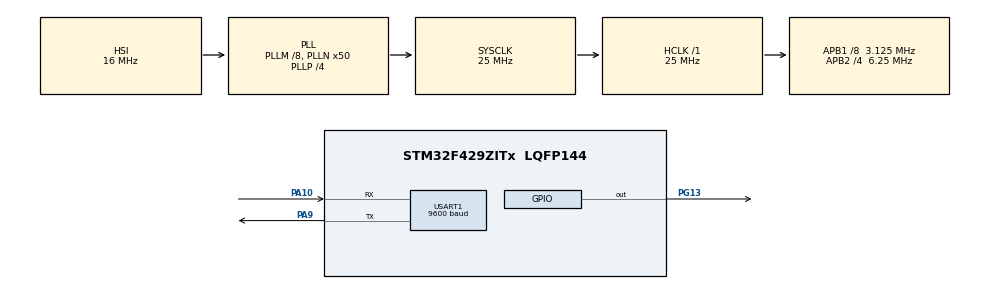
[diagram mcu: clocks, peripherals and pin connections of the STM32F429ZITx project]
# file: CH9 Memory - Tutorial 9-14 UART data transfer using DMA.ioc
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Dma.Request0=USART1_TX
Dma.USART1_TX.0.Direction=DMA_MEMORY_TO_PERIPH
Dma.USART1_TX.0.FIFOMode=DMA_FIFOMODE_DISABLE
Dma.USART1_TX.0.Instance=DMA2_Stream7
Dma.USART1_TX.0.MemDataAlignment=DMA_MDATAALIGN_BYTE
Dma.USART1_TX.0.MemInc=DMA_MINC_ENABLE
Dma.USART1_TX.0.Mode=DMA_NORMAL
Dma.USART1_TX.0.PeriphDataAlignment=DMA_PDATAALIGN_BYTE
Dma.USART1_TX.0.PeriphInc=DMA_PINC_DISABLE
Dma.USART1_TX.0.Priority=DMA_PRIORITY_LOW
Mcu.Family=STM32F4
Mcu.Name=STM32F429ZITx
Mcu.Package=LQFP144
NVIC.DMA2_Stream7_IRQn=true\:0\:0\:false\:false\:true\:false\:true\:true
NVIC.PriorityGroup=NVIC_PRIORITYGROUP_1
NVIC.TIM1_UP_TIM10_IRQn=true\:1\:0\:true\:false\:true\:true\:true\:true
NVIC.USART1_IRQn=true\:1\:0\:true\:false\:true\:true\:true\:true
PA10.Mode=Asynchronous
PA10.Signal=USART1_RX
PA9.Mode=Asynchronous
PA9.Signal=USART1_TX
PG13.Signal=GPIO_Output
ProjectManager.HeapSize=0x200
ProjectManager.StackSize=0x400
ProjectManager.TargetToolchain=STM32CubeIDE
RCC.48MHZClocksFreq_Value=14285714.285714285
RCC.AHBFreq_Value=25000000
RCC.APB1CLKDivider=RCC_HCLK_DIV8
RCC.APB1Freq_Value=3125000
RCC.APB1TimFreq_Value=6250000
RCC.APB2CLKDivider=RCC_HCLK_DIV4
RCC.APB2Freq_Value=6250000
RCC.APB2TimFreq_Value=12500000
RCC.CortexFreq_Value=25000000
RCC.HCLKFreq_Value=25000000
RCC.HSE_VALUE=8000000
RCC.HSI_VALUE=16000000
RCC.LSE_VALUE=32768
RCC.PLLM=8
RCC.PLLN=50
RCC.PLLP=RCC_PLLP_DIV4
RCC.PLLQ=7
RCC.SYSCLKFreq_VALUE=25000000
RCC.SYSCLKSource=RCC_SYSCLKSOURCE_PLLCLK
RCC.VCOOutputFreq_Value=100000000
TIM1.Period=1000-1
TIM1.Prescaler=12500-1
USART1.BaudRate=9600
USART1.VirtualMode=VM_ASYNC
VP_TIM1_VS_ClockSourceINT.Mode=Internal
board=STM32F429I-DISC1

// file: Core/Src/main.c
/* USER CODE BEGIN Header */
/**
  ******************************************************************************
  * @file           : main.c
  * @brief          : Main program body
  ******************************************************************************
  * @attention
  *
  * Copyright (c) 2024 STMicroelectronics.
  * All rights reserved.
  *
  * This software is licensed under terms that can be found in the LICENSE file
  * in the root directory of this software component.
  * If no LICENSE file comes with this software, it is provided AS-IS.
  *
  ******************************************************************************
  */

	/***************************** Tutorial Tags ******************************
	 Data communication UART Tx, and DMA
	 Timer interrupts
	 GPIO digital output
	 **************************************************************************/

	/* 9.4.5 DMA Usage in C Language: ******************************************
	* Tutorial 9-14: UART data transfer using the DMA module
	*

    In this tutorial on memory to peripheral unit transfer using UART module
    form a project with the following specificvation:

    Every second, Long string will be transmitted to PC via UART using DMA. The
    green LED, connected to pin PG13 of the STM32F4 board, will be toggled every time
    to track data transfer. We will use interrupt of the Timer 1 module to obtain 1 s
    intervals.
	***************************************************************************/
/* USER CODE END Header */
#include "main.h"

/* USER CODE BEGIN Includes */
#include<string.h>
/* USER CODE END Includes */

TIM_HandleTypeDef htim1;

UART_HandleTypeDef huart1;
DMA_HandleTypeDef hdma_usart1_tx;

/* USER CODE BEGIN PV */
char * msg = {"Hello world****************************************************\
		******************************************************************** \
		******************************************************************** \
		*********************************************************************\
		********************************************************************* \
		********************************************************************** \
		*******************************************************Hello world end""\r\n"};
/* USER CODE END PV */

void SystemClock_Config(void);
static void MX_GPIO_Init(void);
static void MX_DMA_Init(void);
static void MX_USART1_UART_Init(void);
static void MX_TIM1_Init(void);

int main(void)
{

  /* MCU Configuration--------------------------------------------------------*/

  /* Reset of all peripherals, Initializes the Flash interface and the Systick. */
  HAL_Init();

  /* Configure the system clock */
  SystemClock_Config();

  /* Initialize all configured peripherals */
  MX_GPIO_Init();
  MX_DMA_Init();
  MX_USART1_UART_Init();
  MX_TIM1_Init();
  /* USER CODE BEGIN 2 */
  // Clear timer update flag in case it is set at start
  if (__HAL_TIM_GET_FLAG(&htim1 , TIM_FLAG_UPDATE) != RESET)
  __HAL_TIM_CLEAR_FLAG(&htim1 , TIM_FLAG_UPDATE);
  // Start timer in interrupt mode
  HAL_TIM_Base_Start_IT(&htim1);

  /* USER CODE END 2 */

  /* Infinite loop */
  while (1)
  {

  }
}

void SystemClock_Config(void)
{
  RCC_OscInitTypeDef RCC_OscInitStruct = {0};
  RCC_ClkInitTypeDef RCC_ClkInitStruct = {0};

  /** Configure the main internal regulator output voltage
  */
  __HAL_RCC_PWR_CLK_ENABLE();
  __HAL_PWR_VOLTAGESCALING_CONFIG(PWR_REGULATOR_VOLTAGE_SCALE3);

  /** Initializes the RCC Oscillators according to the specified parameters
  * in the RCC_OscInitTypeDef structure.
  */
  RCC_OscInitStruct.OscillatorType = RCC_OSCILLATORTYPE_HSI;
  RCC_OscInitStruct.HSIState = RCC_HSI_ON;
  RCC_OscInitStruct.HSICalibrationValue = RCC_HSICALIBRATION_DEFAULT;
  RCC_OscInitStruct.PLL.PLLState = RCC_PLL_ON;
  RCC_OscInitStruct.PLL.PLLSource = RCC_PLLSOURCE_HSI;
  RCC_OscInitStruct.PLL.PLLM = 8;
  RCC_OscInitStruct.PLL.PLLN = 50;
  RCC_OscInitStruct.PLL.PLLP = RCC_PLLP_DIV4;
  RCC_OscInitStruct.PLL.PLLQ = 7;
  if (HAL_RCC_OscConfig(&RCC_OscInitStruct) != HAL_OK)
  {
    Error_Handler();
  }

  /** Initializes the CPU, AHB and APB buses clocks
  */
  RCC_ClkInitStruct.ClockType = RCC_CLOCKTYPE_HCLK|RCC_CLOCKTYPE_SYSCLK
                              |RCC_CLOCKTYPE_PCLK1|RCC_CLOCKTYPE_PCLK2;
  RCC_ClkInitStruct.SYSCLKSource = RCC_SYSCLKSOURCE_PLLCLK;
  RCC_ClkInitStruct.AHBCLKDivider = RCC_SYSCLK_DIV1;
  RCC_ClkInitStruct.APB1CLKDivider = RCC_HCLK_DIV8;
  RCC_ClkInitStruct.APB2CLKDivider = RCC_HCLK_DIV4;

  if (HAL_RCC_ClockConfig(&RCC_ClkInitStruct, FLASH_LATENCY_0) != HAL_OK)
  {
    Error_Handler();
  }
}

static void MX_TIM1_Init(void)
{

  TIM_ClockConfigTypeDef sClockSourceConfig = {0};
  TIM_MasterConfigTypeDef sMasterConfig = {0};

  htim1.Instance = TIM1;
  htim1.Init.Prescaler = 12500-1;
  htim1.Init.CounterMode = TIM_COUNTERMODE_UP;
  htim1.Init.Period = 1000-1;
  htim1.Init.ClockDivision = TIM_CLOCKDIVISION_DIV1;
  htim1.Init.RepetitionCounter = 0;
  htim1.Init.AutoReloadPreload = TIM_AUTORELOAD_PRELOAD_DISABLE;
  if (HAL_TIM_Base_Init(&htim1) != HAL_OK)
  {
    Error_Handler();
  }
  sClockSourceConfig.ClockSource = TIM_CLOCKSOURCE_INTERNAL;
  if (HAL_TIM_ConfigClockSource(&htim1, &sClockSourceConfig) != HAL_OK)
  {
    Error_Handler();
  }
  sMasterConfig.MasterOutputTrigger = TIM_TRGO_RESET;
  sMasterConfig.MasterSlaveMode = TIM_MASTERSLAVEMODE_DISABLE;
  if (HAL_TIMEx_MasterConfigSynchronization(&htim1, &sMasterConfig) != HAL_OK)
  {
    Error_Handler();
  }

}

static void MX_USART1_UART_Init(void)
{

  huart1.Instance = USART1;
  huart1.Init.BaudRate = 9600;
  huart1.Init.WordLength = UART_WORDLENGTH_8B;
  huart1.Init.StopBits = UART_STOPBITS_1;
  huart1.Init.Parity = UART_PARITY_NONE;
  huart1.Init.Mode = UART_MODE_TX_RX;
  huart1.Init.HwFlowCtl = UART_HWCONTROL_NONE;
  huart1.Init.OverSampling = UART_OVERSAMPLING_16;
  if (HAL_UART_Init(&huart1) != HAL_OK)
  {
    Error_Handler();
  }

}

static void MX_DMA_Init(void)
{

  /* DMA controller clock enable */
  __HAL_RCC_DMA2_CLK_ENABLE();

  /* DMA interrupt init */
  /* DMA2_Stream7_IRQn interrupt configuration */
  HAL_NVIC_SetPriority(DMA2_Stream7_IRQn, 0, 0);
  HAL_NVIC_EnableIRQ(DMA2_Stream7_IRQn);

}

static void MX_GPIO_Init(void)
{
  GPIO_InitTypeDef GPIO_InitStruct = {0};

  /* GPIO Ports Clock Enable */
  __HAL_RCC_GPIOA_CLK_ENABLE();
  __HAL_RCC_GPIOG_CLK_ENABLE();

  /*Configure GPIO pin Output Level */
  HAL_GPIO_WritePin(GPIOG, GPIO_PIN_13, GPIO_PIN_RESET);

  /*Configure GPIO pin : PG13 */
  GPIO_InitStruct.Pin = GPIO_PIN_13;
  GPIO_InitStruct.Mode = GPIO_MODE_OUTPUT_PP;
  GPIO_InitStruct.Pull = GPIO_NOPULL;
  GPIO_InitStruct.Speed = GPIO_SPEED_FREQ_LOW;
  HAL_GPIO_Init(GPIOG, &GPIO_InitStruct);

}

/* USER CODE BEGIN 4 */
void HAL_TIM_PeriodElapsedCallback(TIM_HandleTypeDef *htim)
{
	if(htim == &htim1){
		HAL_UART_Transmit_DMA(&huart1, (uint8_t *) msg, strlen(msg));
		HAL_GPIO_TogglePin(GPIOG, GPIO_PIN_13);
	}

}
/* USER CODE END 4 */

void Error_Handler(void)
{
  __disable_irq();
  while (1)
  {
  }
}
